# CPSW0_NUSS_CONTROL register map
Vendor: Texas Instruments
Peripheral module from a debugger description file (folder J7VCL).
Registers are 32-bit, read-write, reset 0x0 unless marked. A register's access mark holds for its fields unless they carry their own. Offsets are as the file gives them; lines under a group give offsets from that group; [hi:lo] are bit positions; {n}, {i} and the like mark numbered series; 'fields as' and 'values as' point back to an identical list; <NAME> marks a mode.

## CPSW0_NUSS_CONTROL
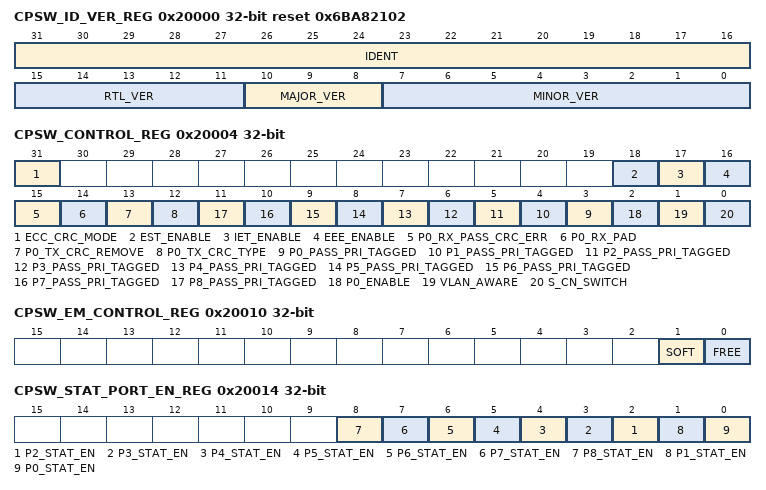
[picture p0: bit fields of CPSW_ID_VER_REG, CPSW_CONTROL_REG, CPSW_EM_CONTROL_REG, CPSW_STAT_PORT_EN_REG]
0x20000 CPSW_ID_VER_REG ro reset 0x6BA82102 — CPSW ID Version Register.
  [31:16] IDENT — Identification Value
  [15:11] RTL_VER — RTL Version Value
  [10:8] MAJOR_VER — Major Version Value
  [7:0] MINOR_VER — Minor Version Value
0x20004 CPSW_CONTROL_REG — CPSW Switch Control
  [31] ECC_CRC_MODE
  [18] EST_ENABLE — Enhanced Scheduled Traffic enable (EST)
  [17] IET_ENABLE — Intersperced Express Traffic enable (IET)
  [16] EEE_ENABLE — Energy Efficient Ethernet enable
  [15] P0_RX_PASS_CRC_ERR — Port 0 Pass Received CRC errors
  [14] P0_RX_PAD — Port 0 Receive Short Packet Pad
  [13] P0_TX_CRC_REMOVE — Port 0 Transmit CRC remove.
  [12] P0_TX_CRC_TYPE
  [n+3] P{n}_PASS_PRI_TAGGED (n=0..8) — Port {n} Pass Priority Tagged
  [2] P0_ENABLE — Port 0 Enable
  [1] VLAN_AWARE — VLAN Aware Mode:
  [0] S_CN_SWITCH — Service or Customer VLAN switch.
0x20010 CPSW_EM_CONTROL_REG — CPSW Emulation Control Register.
  [1] SOFT — Emulation Soft Bit
  [0] FREE — Emulation Free Bit
0x20014 CPSW_STAT_PORT_EN_REG — CPSW Statistics Port Enable Register.
  [n] P{n}_STAT_EN (n=2..8) — Port {n} Statistics Enable (if N &gt; {n})
  [1] P1_STAT_EN — Port 1 Statistics Enable
  [0] P0_STAT_EN — Port 0 Statistics Enable
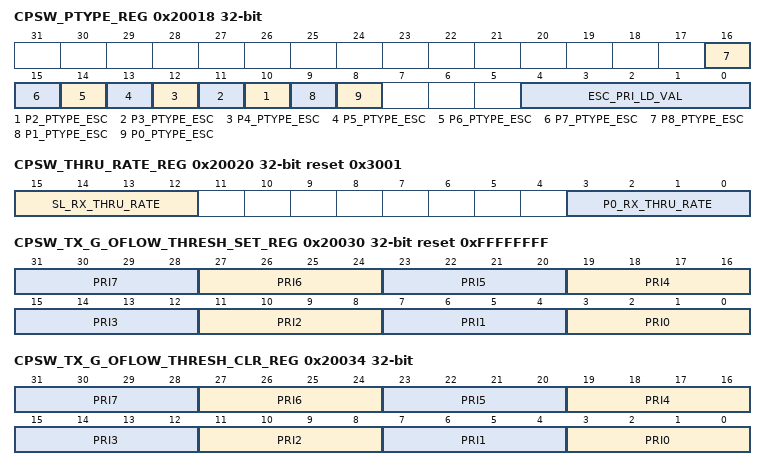
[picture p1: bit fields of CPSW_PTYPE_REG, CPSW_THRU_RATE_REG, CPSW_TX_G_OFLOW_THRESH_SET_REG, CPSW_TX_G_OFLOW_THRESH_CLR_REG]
0x20018 CPSW_PTYPE_REG — CPSW Transmit Priority Type.
  [n+8] P{n}_PTYPE_ESC (n=2..8) — Port {n} Priority Type Escalate (if N &gt; {n})
  [9] P1_PTYPE_ESC — Port 1 Priority Type Escalate
  [8] P0_PTYPE_ESC — Port 0 Priority Type Escalate
  [4:0] ESC_PRI_LD_VAL — Escalate Priority Load Value
0x2001C CPSW_SOFT_IDLE_REG — CPSW Software Idle Register.
  [0] SOFT_IDLE — Software Idle.
0x20020 CPSW_THRU_RATE_REG reset 0x3001 — CPSW Thru Rate Register.
  [15:12] SL_RX_THRU_RATE — Ethernet Port Switch FIFO receive through rate.
  [3:0] P0_RX_THRU_RATE — CPPI FIFO (port 0) receive through rate.
0x20024 CPSW_GAP_THRESH_REG reset 0xB — CPSW Transmit FIFO Short Gap Threshold Register.
  [4:0] GAP_THRESH — Ethernet Port Short Gap Threshold.
0x20028 CPSW_TX_START_WDS_REG reset 0x8 — CPSW Transmit FIFO Start Words Register
  [10:0] TX_START_WDS — FIFO Packet Transmit (egress) Start Words.
0x2002C CPSW_EEE_PRESCALE_REG — CPSW Energy Efficient Ethernet Prescale Value Register.
  [11:0] EEE_PRESCALE — Energy Efficient Ethernet Pre-scale count load value
0x20030 CPSW_TX_G_OFLOW_THRESH_SET_REG reset 0xFFFFFFFF — CPSW PFC Tx Global Out Flow Threshold Set
  [4n+3:4n] PRI{n} (n=0..7) — Priority Based Flow Control Global Outflow Usage Threshold for Pri {n}
0x20034 CPSW_TX_G_OFLOW_THRESH_CLR_REG — CPSW PFC Tx Global Out Flow Threshold Clear Register.
  fields as CPSW_TX_G_OFLOW_THRESH_SET_REG
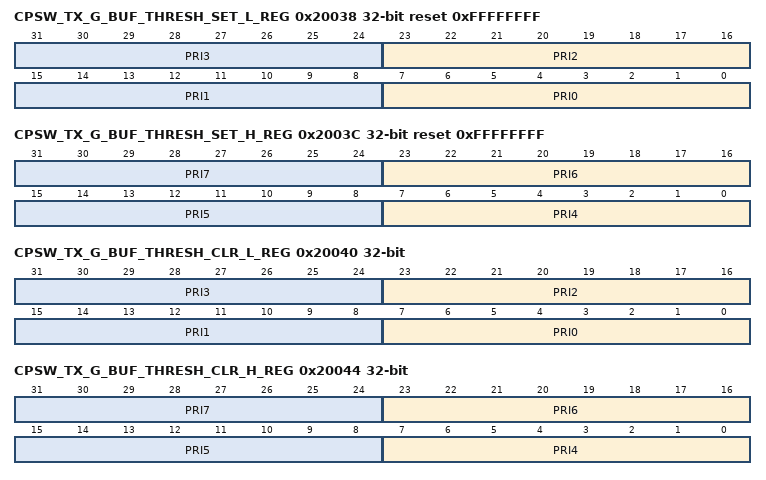
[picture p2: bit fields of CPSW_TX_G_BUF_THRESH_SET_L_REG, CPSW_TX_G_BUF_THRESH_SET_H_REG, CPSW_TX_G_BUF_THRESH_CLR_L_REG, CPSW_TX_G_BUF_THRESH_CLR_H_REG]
0x20038 CPSW_TX_G_BUF_THRESH_SET_L_REG reset 0xFFFFFFFF — CPSW PFC Global Tx Buffer Threshold Set Low Register.
  [8n+7:8n] PRI{n} (n=0..3) — Priority Based Flow Control Global Buffer Usage Threshold for Priority {n}
0x2003C CPSW_TX_G_BUF_THRESH_SET_H_REG reset 0xFFFFFFFF — CPSW PFC Global Tx Buffer Threshold Set High Register.
  [8n-25:8n-32] PRI{n} (n=4..7) — Priority Based Flow Control Global Buffer Usage Threshold for Priority {n}
0x20040 CPSW_TX_G_BUF_THRESH_CLR_L_REG — CPSW PFC Global Tx Buffer Threshold Clear Low Register.
  fields as CPSW_TX_G_BUF_THRESH_SET_L_REG
0x20044 CPSW_TX_G_BUF_THRESH_CLR_H_REG — CPSW PFC Global Tx Buffer Threshold Clear High Register.
  fields as CPSW_TX_G_BUF_THRESH_SET_H_REG
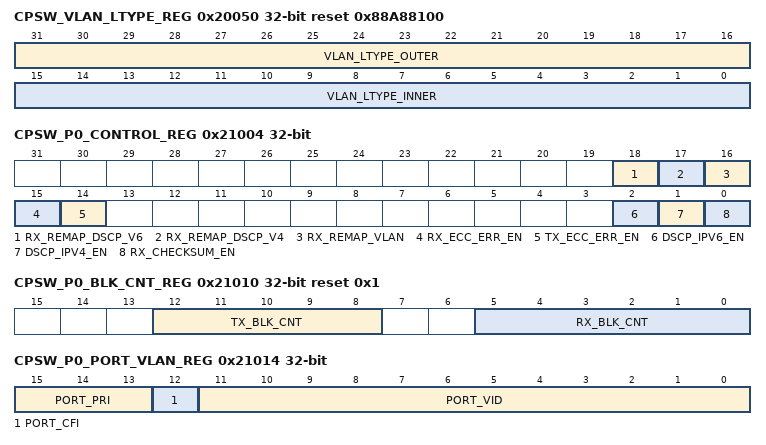
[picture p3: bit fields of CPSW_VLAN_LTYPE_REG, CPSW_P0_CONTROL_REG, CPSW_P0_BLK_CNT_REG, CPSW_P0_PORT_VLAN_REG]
0x20050 CPSW_VLAN_LTYPE_REG reset 0x88A88100 — VLAN LTYPE Outer and Inner Register.
  [31:16] VLAN_LTYPE_OUTER — Outer VLAN LType
  [15:0] VLAN_LTYPE_INNER — Inner VLAN LType
0x20054 CPSW_EST_TS_DOMAIN_REG — Enhanced Scheduled Traffic Host Event Domain Register.
  [7:0] EST_TS_DOMAIN — Enhanced Scheduled Traffic Host Event Domain.
{0x20100+4i} CPSW_TX_PRI{i}_MAXLEN_REG reset 0x7E8 (i=0..6) — Priority {i} Maximum Transmit Packet Length Register.
  [13:0] TX_PRI{i}_MAXLEN — Transmit Priority {i} Maximum Packet Length
0x2011C CPSW_TX_PRI7_MAXLEN_REG reset 0x7E8 — Priority 7 Maximum Transmit Packet Length Register.
  [13:0] TX_PRI7_MAXLEN — Transmit Priority 7 Maximum Packet Length.
0x21004 CPSW_P0_CONTROL_REG — CPPI Port 0 Control Register.
  [18] RX_REMAP_DSCP_V6 — Port 0 receive remap thread to DSCP IPV6 priority.
  [17] RX_REMAP_DSCP_V4 — Port 0 receive remap thread to DSCP IPV6 priority.
  [16] RX_REMAP_VLAN — Port 0 receive remap thread to VLAN.
  [15] RX_ECC_ERR_EN — Port 0 receive ECC Error Enable
  [14] TX_ECC_ERR_EN — Port 0 transmit ECC Error Enable
  [2] DSCP_IPV6_EN — Port 0 IPv6 DSCP enable
  [1] DSCP_IPV4_EN — Port 0 IPV4 DSCP enable
  [0] RX_CHECKSUM_EN — Port 0 Receive (port 0 ingress) Checksum Enable
0x21008 CPSW_P0_FLOW_ID_OFFSET_REG — CPPI Port 0 Flow ID Offset Register.
  [13:0] VALUE — This value is added to the thread/Flow_ID in CPPI transmit PSI Info Word 0
0x21010 CPSW_P0_BLK_CNT_REG ro reset 0x1 — CPPI Port 0 FIFO Block Usage Count Register.
  [12:8] TX_BLK_CNT — Port 0 Transmit Block Count Usage.
  [5:0] RX_BLK_CNT — Port 0 Receive Block Count Usage.
0x21014 CPSW_P0_PORT_VLAN_REG — CPPI Port 0 VLAN
  [15:13] PORT_PRI — Port VLAN Priority
  [12] PORT_CFI — Port CFI bit
  [11:0] PORT_VID — Port VLAN ID
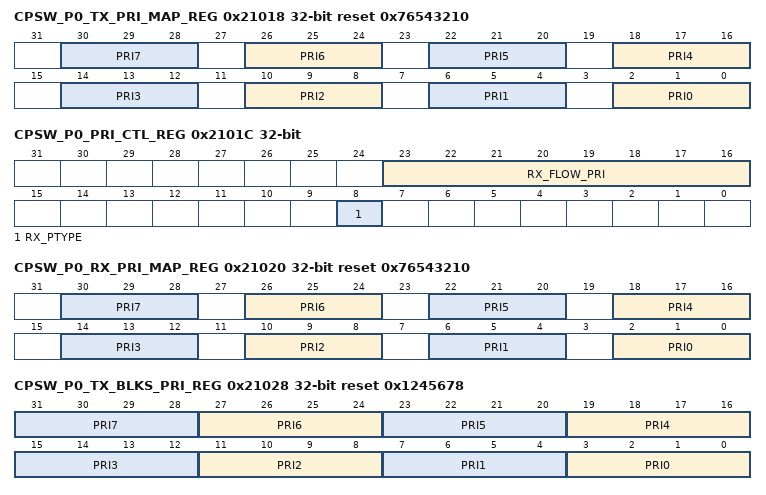
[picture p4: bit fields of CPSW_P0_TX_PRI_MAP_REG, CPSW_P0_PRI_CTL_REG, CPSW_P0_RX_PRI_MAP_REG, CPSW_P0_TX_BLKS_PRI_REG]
0x21018 CPSW_P0_TX_PRI_MAP_REG reset 0x76543210 — CPPI Port 0 Tx Header Pri to Switch Pri Mapping.
  [4n+2:4n] PRI{n} (n=0..7) — Priority {n}.
0x2101C CPSW_P0_PRI_CTL_REG — CPPI Port 0 Priority Control.
  [23:16] RX_FLOW_PRI — Receive Priority Based Flow Control Enable (per priority).
  [8] RX_PTYPE — Receive Priority Type
0x21020 CPSW_P0_RX_PRI_MAP_REG reset 0x76543210 — CPPI Port 0 RX Pkt Pri to Header Pri Map
  [4n+2:4n] PRI{n} (n=0..7) — Priority {n}.
0x21024 CPSW_P0_RX_MAXLEN_REG reset 0x5EE — CPPI Port 0 Receive Frame Max Length.
  [13:0] RX_MAXLEN — RX Maximum Frame Length.
0x21028 CPSW_P0_TX_BLKS_PRI_REG reset 0x1245678 — CPPI Port 0 Transmit Block Sub Per Priority Register.
  [4n+3:4n] PRI{n} (n=0..7) — Priority {n} Port Transmit Blocks
0x21030 CPSW_P0_IDLE2LPI_REG — Port 0 EEE LPI to wake counter load value.
  [23:0] COUNT — Port 0 EEE Idle to LPI counter load value
0x21034 CPSW_P0_LPI2WAKE_REG — Port 0 EEE LPI to wake counter
  [23:0] COUNT — Port 0 EEE LPI to wake counter load value
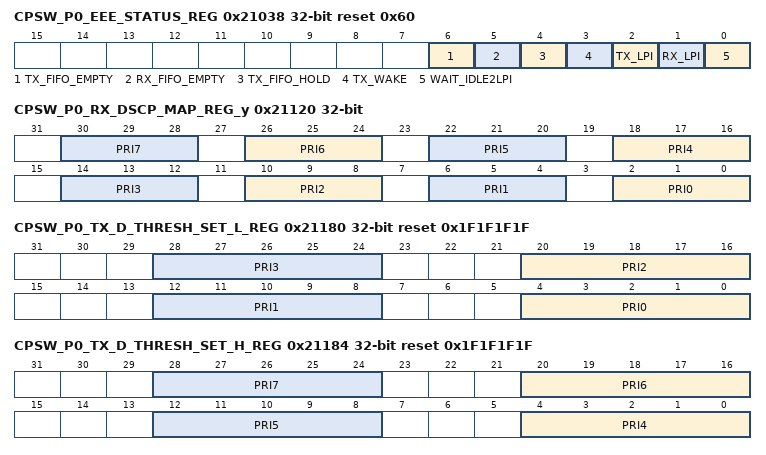
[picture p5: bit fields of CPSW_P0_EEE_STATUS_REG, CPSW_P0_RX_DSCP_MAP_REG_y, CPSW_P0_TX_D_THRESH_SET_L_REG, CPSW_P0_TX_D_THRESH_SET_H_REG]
0x21038 CPSW_P0_EEE_STATUS_REG ro reset 0x60 — Port 0 EEE status.
  [6] TX_FIFO_EMPTY — CPPI (Port 0) Transmit FIFO packet count zero.
  [5] RX_FIFO_EMPTY — CPPI (Port 0) Receive FIFO packet count zero.
  [4] TX_FIFO_HOLD — CPPI (Port 0) Transmit FIFO hold.
  [3] TX_WAKE — CPPI (Port 0) Receive Wake Time.
  [2] TX_LPI — CPPI (Port 0) transmit LPI state.
  [1] RX_LPI — CPPI (Port 0) receive LPI state.
  [0] WAIT_IDLE2LPI — CPPI (Port 0) Transmit Wait Idle to LPI.
0x21050 CPSW_P0_FIFO_STATUS_REG ro — Port 0 FIFO Status
  [7:0] TX_PRI_ACTIVE — Port 0 Transmit FIFO Priority Active.
0x21120 CPSW_P0_RX_DSCP_MAP_REG_y — CPPI Port 0 Receive IPV4/IPV6 DSCP Map 0 to Map 7 Registers. Offset = 00021120h + (y * 4h); where y = 0h to 7h
  [4n+2:4n] PRI{n} (n=0..7) — A DSCP IPV4/V6 packet TOS of N*8+{n} is mapped to this received priority
0x21140 CPSW_P0_PRI_CIR_REG_y — CPPI Port 0 Rx Priority 0 to Priority 7 Committed Information Rate Registers. Offset = 00021140h + (y * 4h); where y = 0h to 7h
  [27:0] PRI_CIR — Priority 'y' Committed Information Rate Count Value
0x21160 CPSW_P0_PRI_EIR_REG_y — CPPI Port 0 Rx Priority 0 to Priority 7 Excess Information Rate. Offset = 00021160h + (y * 4h); where y = 0h to 7h
  [27:0] PRI_EIR — Priority N EIR
0x21180 CPSW_P0_TX_D_THRESH_SET_L_REG reset 0x1F1F1F1F — CPPI Port 0 Tx PFC Destination Threshold Set Low
  [8n+4:8n] PRI{n} (n=0..3) — Port Priority Based Flow Control Threshold Set Value for Priority {n}
0x21184 CPSW_P0_TX_D_THRESH_SET_H_REG reset 0x1F1F1F1F — CPPI Port 0 Tx PFC Destination Threshold Set High
  [8n-28:8n-32] PRI{n} (n=4..7) — Port Priority Based Flow Control Threshold Set Value for Priority {n}
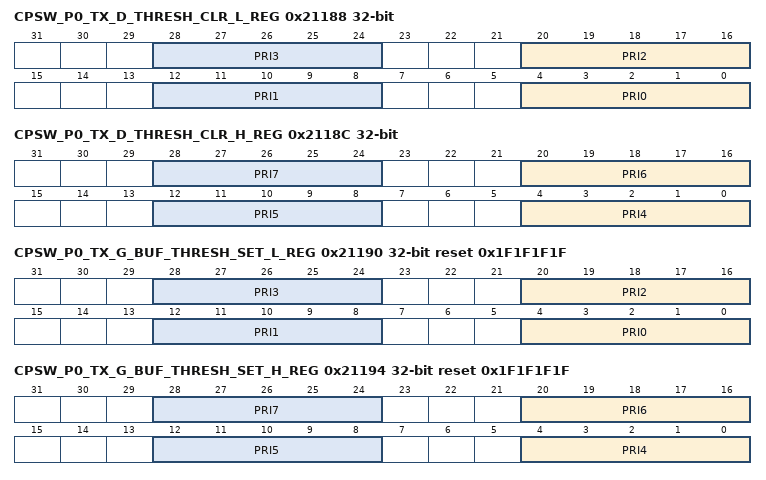
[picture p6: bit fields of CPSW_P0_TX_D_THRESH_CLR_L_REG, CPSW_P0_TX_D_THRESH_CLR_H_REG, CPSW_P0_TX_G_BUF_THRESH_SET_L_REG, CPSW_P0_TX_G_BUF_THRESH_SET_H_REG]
0x21188 CPSW_P0_TX_D_THRESH_CLR_L_REG — CPPI Port 0 Tx PFC Destination Threshold Clr Low
  [8n+4:8n] PRI{n} (n=0..3) — Port Priority Based Flow Control Threshold Clear Value for Priority {n}
0x2118C CPSW_P0_TX_D_THRESH_CLR_H_REG — CPPI Port 0 Tx PFC Destination Threshold Clr High
  [8n-28:8n-32] PRI{n} (n=4..7) — Port Priority Based Flow Control Threshold Clear Value for Priority {n}
0x21190 CPSW_P0_TX_G_BUF_THRESH_SET_L_REG reset 0x1F1F1F1F — CPPI Port 0 Tx PFC Global Buffer Threshold Set Low
  fields as CPSW_P0_TX_D_THRESH_SET_L_REG
0x21194 CPSW_P0_TX_G_BUF_THRESH_SET_H_REG reset 0x1F1F1F1F — CPPI Port 0 Tx PFC Global Buffer Threshold Set High
  fields as CPSW_P0_TX_D_THRESH_SET_H_REG
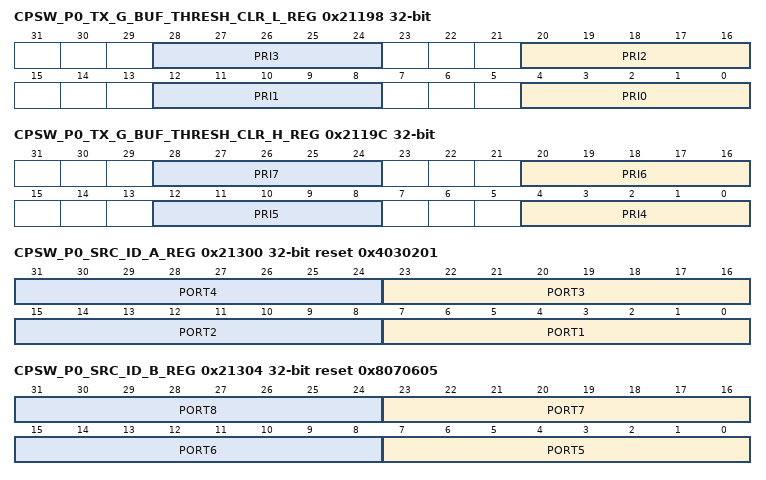
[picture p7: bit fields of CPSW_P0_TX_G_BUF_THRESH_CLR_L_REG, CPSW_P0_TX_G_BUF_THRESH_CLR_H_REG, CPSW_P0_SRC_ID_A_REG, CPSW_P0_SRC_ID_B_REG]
0x21198 CPSW_P0_TX_G_BUF_THRESH_CLR_L_REG — CPPI Port 0 Tx PFC Global Buffer Threshold Clr Low
  fields as CPSW_P0_TX_D_THRESH_CLR_L_REG
0x2119C CPSW_P0_TX_G_BUF_THRESH_CLR_H_REG — CPPI Port 0 Tx PFC Global Buffer Threshold Clr High
  fields as CPSW_P0_TX_D_THRESH_CLR_H_REG
0x21300 CPSW_P0_SRC_ID_A_REG reset 0x4030201 — CPPI Port 0 CPPI Source ID A.
  [8n-1:8n-8] PORT{n} (n=1..4) — Port {n} CPPI Info Word0 Source ID Value.
0x21304 CPSW_P0_SRC_ID_B_REG reset 0x8070605 — CPPI Port 0 CPPI Source ID B.
  [8n-33:8n-40] PORT{n} (n=5..8) — Port {n} CPPI Info Word0 Source ID Value.
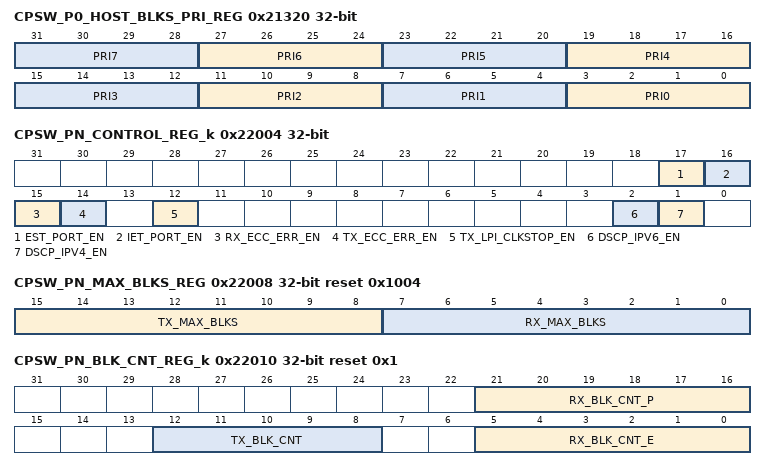
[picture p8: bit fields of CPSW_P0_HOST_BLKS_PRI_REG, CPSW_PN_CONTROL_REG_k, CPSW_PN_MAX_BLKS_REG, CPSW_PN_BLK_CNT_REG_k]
0x21320 CPSW_P0_HOST_BLKS_PRI_REG — CPPI Port 0 Host Blocks Priority
  [4n+3:4n] PRI{n} (n=0..7) — Priority {n} Host Blocks
0x22000 CPSW_PN_RESERVED_REG_k ro — Reserved.
0x22004 CPSW_PN_CONTROL_REG_k — Enet Port N Control. Offset = 00022004h + (k * 1000h); where k = 0h to 3h
  [17] EST_PORT_EN — EST Port Enable.
  [16] IET_PORT_EN — Intersperced Express Traffic (IET) Port Enable.
  [15] RX_ECC_ERR_EN — Port N receive ECC Error Enable
  [14] TX_ECC_ERR_EN — Port N transmit ECC Error Enable
  [12] TX_LPI_CLKSTOP_EN — Transmit LPI Clock Stop Enable.
  [2] DSCP_IPV6_EN — IPV6 DSCP enable
  [1] DSCP_IPV4_EN — IPV4 DSCP enable
0x22008 CPSW_PN_MAX_BLKS_REG reset 0x1004 — Enet Port N FIFO Max Blocks.
  [15:8] TX_MAX_BLKS — Transmit Max Blocks.
  [7:0] RX_MAX_BLKS — Receive Max Blocks.
0x22010 CPSW_PN_BLK_CNT_REG_k ro reset 0x1 — Enet Port N FIFO Block Usage Count Offset = 00022010h + (N * 1000h); where k = 0h to 3h
  [21:16] RX_BLK_CNT_P — Receive Express Block Count Usage.
  [12:8] TX_BLK_CNT — Transmit Block Count Usage.
  [5:0] RX_BLK_CNT_E — Receive Express Block Count Usage.
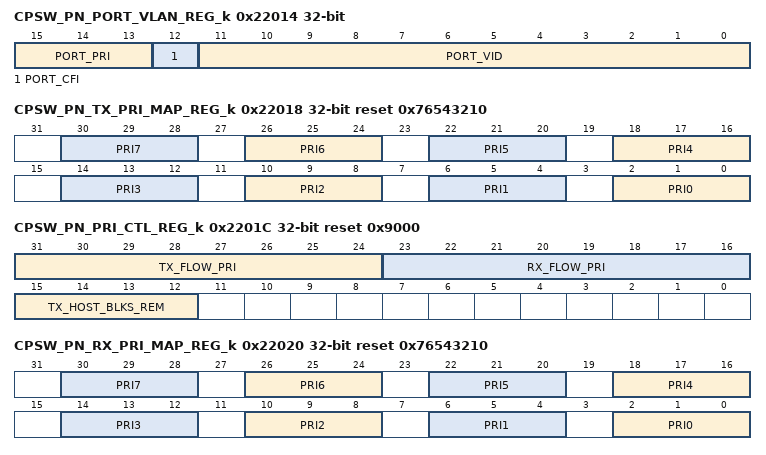
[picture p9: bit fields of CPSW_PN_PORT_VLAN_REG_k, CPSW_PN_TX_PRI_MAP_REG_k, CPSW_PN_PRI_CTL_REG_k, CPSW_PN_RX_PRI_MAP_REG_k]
0x22014 CPSW_PN_PORT_VLAN_REG_k — Enet Port N VLAN Offset = 00022014h + (k * 1000h); where k = 0h to 3h
  fields as CPSW_P0_PORT_VLAN_REG
0x22018 CPSW_PN_TX_PRI_MAP_REG_k reset 0x76543210 — Enet Port N Tx Header Pri to Switch Pri Mapping Offset = 00022018h + (k * 1000h); where k = 0h to 3h
  [4n+2:4n] PRI{n} (n=0..7) — Priority {n}. A packet header priority of {n}h is given this switch queue pri.
0x2201C CPSW_PN_PRI_CTL_REG_k reset 0x9000 — Enet Port N Priority Control Offset = 0002201Ch + (k * 1000h); where k = 0h to 3h
  [31:24] TX_FLOW_PRI — Transmit Priority Based Flow Control Enable (per priority)
  [23:16] RX_FLOW_PRI — Receive Priority Based Flow Control Enable (per priority)
  [15:12] TX_HOST_BLKS_REM — Transmit FIFO Blocks that must be free before a non rate-limited CPPI Port 0 receive thread can begin sending a packet
0x22020 CPSW_PN_RX_PRI_MAP_REG_k reset 0x76543210 — Enet Port N RX Pkt Pri to Header Pri Map Offset = 00022020h + (k * 1000h); where k = 0h to 3h
  [4n+2:4n] PRI{n} (n=0..7) — Priority {n}.
0x22024 CPSW_PN_RX_MAXLEN_REG_k reset 0x5EE — Enet Port N Receive Frame Max Length. Offset = 00022024h + (k * 1000h); where k = 0h to 3h
  [13:0] RX_MAXLEN — RX Maximum Frame Length.
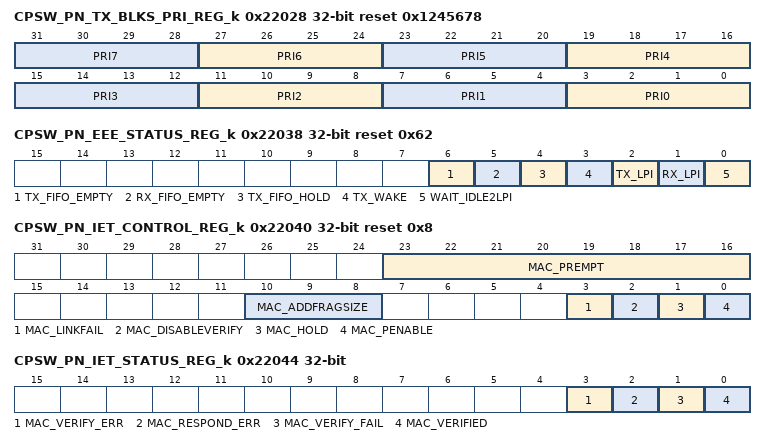
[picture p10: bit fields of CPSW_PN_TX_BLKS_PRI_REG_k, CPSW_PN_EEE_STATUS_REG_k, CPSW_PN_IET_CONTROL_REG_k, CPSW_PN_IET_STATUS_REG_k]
0x22028 CPSW_PN_TX_BLKS_PRI_REG_k reset 0x1245678 — Enet Port N Transmit Block Sub Per Priority Offset = 00022028h + (k * 1000h); where k = 0h to 3h
  [4n+3:4n] PRI{n} (n=0..7) — Priority {n} Port Transmit Blocks
0x22030 CPSW_PN_IDLE2LPI_REG_k — Enet Port N EEE Idle to LPI counter Offset = 00022030h + (k * 1000h); where k = 0h to 3h
  [23:0] COUNT — EEE Idle to LPI counter load value
0x22034 CPSW_PN_LPI2WAKE_REG_k — Enet Port N EEE LPI to wake counter Offset = 00022034h + (k * 1000h); where k = 0h to 3h
  [23:0] COUNT — EEE LPI to wake counter load value
0x22038 CPSW_PN_EEE_STATUS_REG_k ro reset 0x62 — Enet Port N EEE status Offset = 00022038h + (k * 1000h); where k = 0h to 3h
  [6] TX_FIFO_EMPTY — Port N Transmit FIFO packet count zero.
  [5] RX_FIFO_EMPTY — Port N Receive FIFO packet count zero.
  [4] TX_FIFO_HOLD — Port N Transmit FIFO hold.
  [3] TX_WAKE — Port N Receive Wake Time.
  [2] TX_LPI — Port N Transmit LPI.
  [1] RX_LPI — Port N Receive LPI.
  [0] WAIT_IDLE2LPI — Transmit Wait Idle to LPI.
0x22040 CPSW_PN_IET_CONTROL_REG_k reset 0x8 — Enet Port N IET Control Offset = 00022040h + (k * 1000h); where k = 0h to 3h
  [23:16] MAC_PREMPT — Mac Preempt Queue – Indicates which transmit FIFO queues are sent to the preempt MAC. Bit 0 indicates queue zero, bit 1 queue 1 and so on. Packets will be sent to the preempt MAC only when MAC_PENABLE is set, and when MAC_VERIFIED (fromCPSW_PN_IET_STATUS_REG_k) or MAC_DISABLEVERIFY is set, and when IET_PORT_EN is set.
  [10:8] MAC_ADDFRAGSIZE — Mac Fragment Size – An integer in the range 0:7 indicating, as a multiple of 64, the minimum additional length for nonfinal mPackets. 0 = 64 1 = 128 2 = 192 3 = 256 4 = 320 5 = 384 6 = 448 7 = 512
  [3] MAC_LINKFAIL — Mac Link Fail – Link Fail Indicator to reset the verify state machine. This bit is reset high. Verify and response frames will be sent/allowed when this bit is cleared.
  [2] MAC_DISABLEVERIFY — Mac Disable Verify – Disables verification on the port when set. If this bit is set then packets will be sent to the preempt Mac when MAC_PENABLE is set (This is a forced mode with no IET verification).
  [1] MAC_HOLD — Mac Hold – Hold Preemption on the port.
  [0] MAC_PENABLE — Mac Preemption Enable – Port Preemption Enable. This takes effect only when IET_PORT_EN is set.
0x22044 CPSW_PN_IET_STATUS_REG_k ro — Enet Port N IET Status Offset = 00022044h + (k * 1000h); where k = 0h to 3h
  [3] MAC_VERIFY_ERR — Mac Received Verify Packet with Errors – Set when a verify packet with errors is received. Cleared when MAC_PENABLE is cleared to zero.
  [2] MAC_RESPOND_ERR — Mac Received Respond Packet with Errors – Set when a respond packet with errors is received. Cleared when MAC_PENABLE is cleared to zero.
  [1] MAC_VERIFY_FAIL — Mac Verification Failed – Indication that verification was unsuccessful.
  [0] MAC_VERIFIED — Mac Verified – Indication that verification was successful.
0x22048 CPSW_PN_IET_VERIFY_REG_k reset 0x1312D0 — Enet Port N IET VERIFY Offset = 00022048h + (k * 1000h); where k = 0h to 3h
  [23:0] MAC_VERIFY_CNT — Mac Verify Timeout Count – The number of wireside clocks contained in the verify timeout counter. The default is 0x1312D0 (10ms at 125MHz in gig mode).
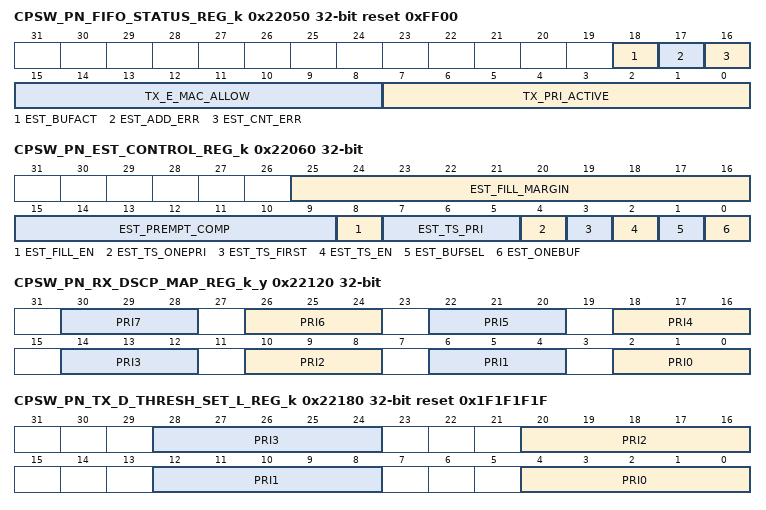
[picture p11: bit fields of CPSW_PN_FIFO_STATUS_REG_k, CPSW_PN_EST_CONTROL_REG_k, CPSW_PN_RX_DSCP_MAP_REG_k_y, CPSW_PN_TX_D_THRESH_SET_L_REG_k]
0x22050 CPSW_PN_FIFO_STATUS_REG_k ro reset 0xFF00 — Enet Port N FIFO STATUS Offset = 00022050h + (k * 1000h); where k = 0h to 3h
  [18] EST_BUFACT — EST RAM active buffer.
  [17] EST_ADD_ERR — EST Address Error.
  [16] EST_CNT_ERR — EST Fetch Count Error.
  [15:8] TX_E_MAC_ALLOW — EST transmit MAC allow.
  [7:0] TX_PRI_ACTIVE — EST Transmit Priority Active.
0x22060 CPSW_PN_EST_CONTROL_REG_k — Enet Port N EST CONTROL Offset = 00022060h + (k * 1000h); where k = 0h to 3h
  [25:16] EST_FILL_MARGIN
  [15:9] EST_PREMPT_COMP — EST Prempt Comparison Value.
  [8] EST_FILL_EN — EST Fill Enable.
  [7:5] EST_TS_PRI — EST Timestamp Express Priority.
  [4] EST_TS_ONEPRI — EST Timestamp One Express Priority.
  [3] EST_TS_FIRST — EST Timestamp First Express Packet only.
  [2] EST_TS_EN — EST Timestamp Enable.
  [1] EST_BUFSEL — EST Buffer Select.
  [0] EST_ONEBUF — EST One Fetch Buffer.
0x22120 CPSW_PN_RX_DSCP_MAP_REG_k_y — Enet Port N Receive IPV4/IPV6 DSCP Map M Offset = 00022120h + (k * 1000h) + (y * 4h); where k = 0h to 3h, y = 0h to 7h
  fields as CPSW_P0_RX_DSCP_MAP_REG_y
0x22140 CPSW_PN_PRI_CIR_REG_k_y — Enet Port N Rx Priority P Committed Information Rate Value Offset = 00022140h + (k * 1000h) + (y * 4h); where k = 0h to 3h, y = 0h to 7h
  [27:0] PRI_CIR — Priority N committed information rate
0x22160 CPSW_PN_PRI_EIR_REG_k_y — Enet Port N Rx Priority P Excess Informatoin Rate Value. Offset = 00022160h + (k * 1000h) + (y * 4h); where k = 0h to 3h, y = 0h to 7h
  [27:0] PRI_EIR — Priority N Excess Information Rate count
0x22180 CPSW_PN_TX_D_THRESH_SET_L_REG_k reset 0x1F1F1F1F — Enet Port N Tx PFC Destination Threshold Set Low. Offset = 00022180h + (k * 1000h); where k = 0h to 3h
  fields as CPSW_P0_TX_D_THRESH_SET_L_REG
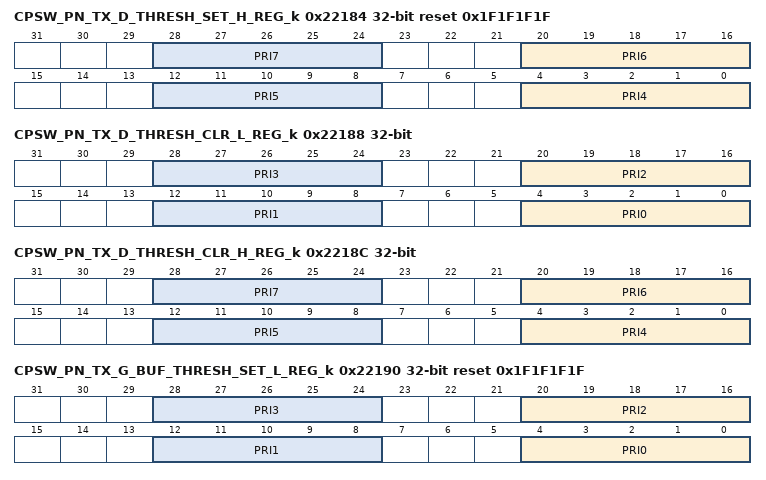
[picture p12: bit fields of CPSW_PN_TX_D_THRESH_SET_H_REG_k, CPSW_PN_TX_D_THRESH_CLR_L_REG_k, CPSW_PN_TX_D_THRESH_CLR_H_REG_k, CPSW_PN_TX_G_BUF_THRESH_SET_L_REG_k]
0x22184 CPSW_PN_TX_D_THRESH_SET_H_REG_k reset 0x1F1F1F1F — Enet Port N Tx PFC Destination Threshold Set High. Offset = 00022184h + (k * 1000h); where k = 0h to 3h
  fields as CPSW_P0_TX_D_THRESH_SET_H_REG
0x22188 CPSW_PN_TX_D_THRESH_CLR_L_REG_k — Enet Port N Tx PFC Destination Threshold Clr Low. Offset = 00022188h + (k * 1000h); where k = 0h to 3h
  fields as CPSW_P0_TX_D_THRESH_CLR_L_REG
0x2218C CPSW_PN_TX_D_THRESH_CLR_H_REG_k — Enet Port N Tx PFC Destination Threshold Clr High. Offset = 0002218Ch + (k * 1000h); where k = 0h to 3h
  fields as CPSW_P0_TX_D_THRESH_CLR_H_REG
0x22190 CPSW_PN_TX_G_BUF_THRESH_SET_L_REG_k reset 0x1F1F1F1F — Enet Port N Tx PFC Global Buffer Threshold Set Low. Offset = 00022190h + (k * 1000h); where k = 0h to 3h
  fields as CPSW_P0_TX_D_THRESH_SET_L_REG
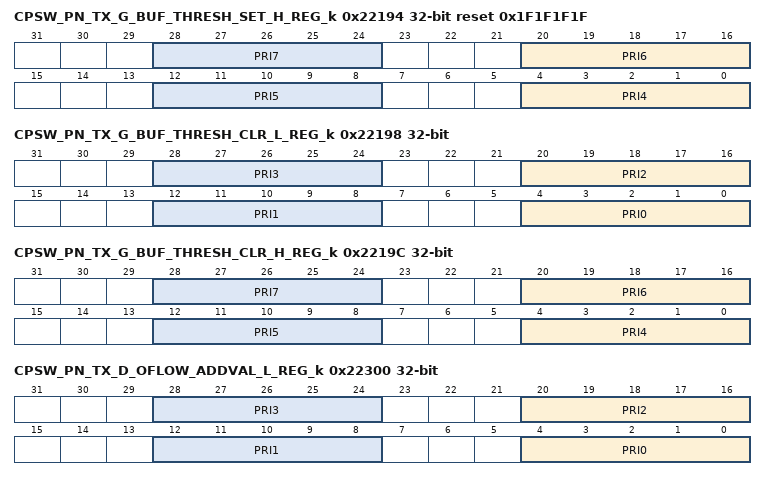
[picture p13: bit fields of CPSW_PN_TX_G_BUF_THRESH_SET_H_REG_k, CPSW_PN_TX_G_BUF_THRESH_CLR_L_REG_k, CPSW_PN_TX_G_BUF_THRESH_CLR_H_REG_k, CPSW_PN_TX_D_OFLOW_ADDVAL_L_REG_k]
0x22194 CPSW_PN_TX_G_BUF_THRESH_SET_H_REG_k reset 0x1F1F1F1F — Enet Port N Tx PFC Global Buffer Threshold Set High. Offset = 00022194h + (k * 1000h); where k = 0h to 3h
  fields as CPSW_P0_TX_D_THRESH_SET_H_REG
0x22198 CPSW_PN_TX_G_BUF_THRESH_CLR_L_REG_k — Enet Port N Tx PFC Global Buffer Threshold Clr Low Offset = 00022198h + (k * 1000h); where k = 0h to 3h
  fields as CPSW_P0_TX_D_THRESH_CLR_L_REG
0x2219C CPSW_PN_TX_G_BUF_THRESH_CLR_H_REG_k — Enet Port N Tx PFC Global Buffer Threshold Clr High Offset = 0002219Ch + (k * 1000h); where k = 0h to 3h
  fields as CPSW_P0_TX_D_THRESH_CLR_H_REG
0x22300 CPSW_PN_TX_D_OFLOW_ADDVAL_L_REG_k — Enet Port N Tx Destination Out Flow Add Values Low. Offset = 00022300h + (k * 1000h); where k = 0h to 3h
  [8n+4:8n] PRI{n} (n=0..3) — Port PFC Destination Based Out Flow Add Value for Priority {n}
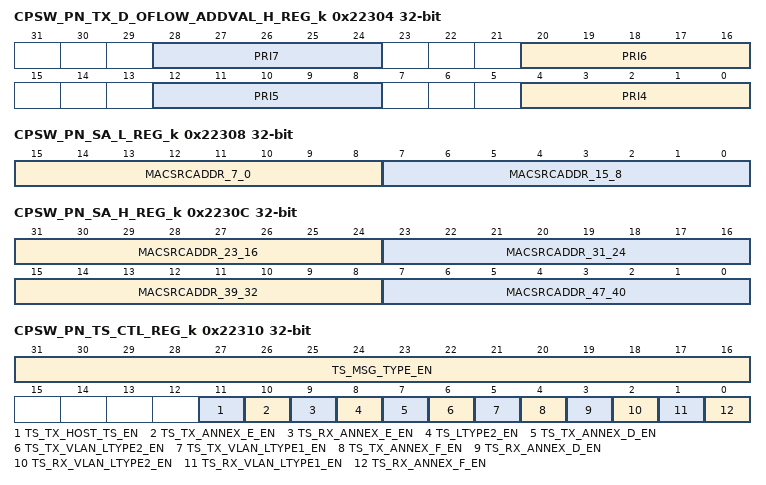
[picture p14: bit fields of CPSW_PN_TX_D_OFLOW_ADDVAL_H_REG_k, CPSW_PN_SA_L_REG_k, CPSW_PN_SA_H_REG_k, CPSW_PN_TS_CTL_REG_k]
0x22304 CPSW_PN_TX_D_OFLOW_ADDVAL_H_REG_k — Enet Port N Tx Destination Out Flow Add Values High. Offset = 00022304h + (k * 1000h); where k = 0h to 3h
  [8n-28:8n-32] PRI{n} (n=4..7) — Port PFC Destination Based Out Flow Add Value for Priority {n}
0x22308 CPSW_PN_SA_L_REG_k — Enet Port N Tx Pause Frame Source Address Low Offset = 00022308h + (k * 1000h); where k = 0h to 3h
  [15:8] MACSRCADDR_7_0 — Source Address Lower 8 bits (byte 0)
  [7:0] MACSRCADDR_15_8 — Source Address bits 15-8 (byte 1)
0x2230C CPSW_PN_SA_H_REG_k — Enet Port N Tx Pause Frame Source Address High. Offset = 0002230Ch + (k * 1000h); where k = 0h to 3h
  [31:24] MACSRCADDR_23_16 — Source Address bits 23-16 (byte 2)
  [23:16] MACSRCADDR_31_24 — Source Address bits 31-24 (byte 3)
  [15:8] MACSRCADDR_39_32 — Source Address bits 39-32 (byte 4)
  [7:0] MACSRCADDR_47_40 — Source Address bits 47-40 (byte 5)
0x22310 CPSW_PN_TS_CTL_REG_k — Enet Port N Time Sync Control Offset = 00022310h + (k * 1000h); where k = 0h to 3h
  [31:16] TS_MSG_TYPE_EN — Time Sync Message Type Enable.
  [11] TS_TX_HOST_TS_EN — Time Sync Transmit Host Time Stamp Enable.
  [10] TS_TX_ANNEX_E_EN — Time Sync Transmit Annex E enable.
  [9] TS_RX_ANNEX_E_EN — Time Sync Receive Annex E enable.
  [8] TS_LTYPE2_EN — Time Sync LTYPE 2 enable (transmit and receive).
  [7] TS_TX_ANNEX_D_EN — Time Sync Transmit Annex D enable.
  [6] TS_TX_VLAN_LTYPE2_EN — Time Sync Transmit VLAN LTYPE 2 enable.
  [5] TS_TX_VLAN_LTYPE1_EN — Time Sync Transmit VLAN LTYPE 1 enable.
  [4] TS_TX_ANNEX_F_EN — Time Sync Transmit Annex F enable.
  [3] TS_RX_ANNEX_D_EN — Time Sync Receive Annex D enable.
  [2] TS_RX_VLAN_LTYPE2_EN — Time Sync Receive VLAN LTYPE 2 enable.
  [1] TS_RX_VLAN_LTYPE1_EN — Time Sync Receive VLAN LTYPE 1 enable.
  [0] TS_RX_ANNEX_F_EN — Time Sync Receive Annex F Enable.
0x22314 CPSW_PN_TS_SEQ_LTYPE_REG_k reset 0x1E0000 — Enet Port N Time Sync LTYPE (and SEQ_ID_OFFSET). Offset = 00022314h + (k * 1000h); where k = 0h to 3h
  [21:16] TS_SEQ_ID_OFFSET — Time Sync Sequence ID Offset
  [15:0] TS_LTYPE1 — Time Sync LTYPE1
0x22318 CPSW_PN_TS_VLAN_LTYPE_REG_k — Enet Port N Time Sync VLAN2 and VLAN2. Offset = 00022318h + (k * 1000h); where k = 0h to 3h
  [31:16] TS_VLAN_LTYPE2 — Time Sync VLAN LTYPE2
  [15:0] TS_VLAN_LTYPE1 — Time Sync VLAN LTYPE1
0x2231C CPSW_PN_TS_CTL_LTYPE2_REG_k — Enet Port N Time Sync Control and LTYPE 2. Offset = 0002231Ch + (k * 1000h); where k = 0h to 3h
  [24] TS_UNI_EN — Time Sync Unicast Enable
  [23] TS_TTL_NONZERO — Time Sync Time to Live Non-zero Enable
  [22] TS_320 — Time Sync Destination IP Address 320 Enable
  [21] TS_319 — Time Sync Destination IP Address 319 Enable
  [n-112] TS_{n} (n=129..132) — Time Sync Destination IP Address {n} Enable
  [16] TS_107 — Time Sync Destination IP Address 107 Enable
  [15:0] TS_LTYPE2 — Time Sync LTYPE2
0x22320 CPSW_PN_TS_CTL2_REG_k reset 0x40000 — Enet Port N Time Sync Control 2. Offset = 00022320h + (k * 1000h); where k = 0h to 3h
  [21:16] TS_DOMAIN_OFFSET — Time Sync Domain Offset
  [15:0] TS_MCAST_TYPE_EN — Time Sync Multicast Destination Address Type Enable
0x22330 CPSW_PN_MAC_CONTROL_REG_k — Enet Port N Mac Control. Offset = 00022330h + (k * 1000h); where k = 0h to 3h
  [25] EXT_EN_XGIG — 10G External Enable
  [24] RX_CMF_EN — RX Copy MAC Control Frames Enable.
  [23] RX_CSF_EN — RX Copy Short Frames Enable.
  [22] RX_CEF_EN — RX Copy Error Frames Enable.
  [21] TX_SHORT_GAP_LIM_EN — Transmit Short Gap Limit Enable
  [20] EXT_TX_FLOW_EN — External Transmit Flow Control Enable.
  [19] EXT_RX_FLOW_EN — External Receive Flow Control Enable.
  [18] EXT_EN — External Control Enable.
  [17] GIG_FORCE — Gigabit Mode Force.
  [16] IFCTL_B — Interface Control B.
  [15] IFCTL_A — Interface Control A.
  [13] XGMII_EN — XGMII Enable.
  [12] CRC_TYPE — Port CRC Type.
  [11] CMD_IDLE — Command Idle.
  [10] TX_SHORT_GAP_ENABLE — Transmit Short Gap Enable.
  [8] XGIG — 10 Gigabit Mode.Note: 10 Gigabit Mode is not supported on this device.
  [7] GIG — Gigabit Mode.
  [6] TX_PACE — Transmit Pacing Enable
  [5] GMII_EN — GMII Enable.
  [4] TX_FLOW_EN — Transmit Flow Control Enable.
  [3] RX_FLOW_EN — Receive Flow Control Enable.
  [2] MTEST — Manufacturing Test mode.
  [1] LOOPBACK — Loop Back Mode.
  [0] FULLDUPLEX — Full Duplex mode.
0x22334 CPSW_PN_MAC_STATUS_REG_k ro reset 0xF0000000 — Enet Port N Mac Status Offset = 00022334h + (k * 1000h); where k = 0h to 3h
  [31] IDLE — Enet IDLE.
  [30] E_IDLE — Express MAC is Idle.
  [29] P_IDLE — Prempt MAC is Idle.
  [28] MAC_TX_IDLE — Mac Transmit Idle.
  [27] TORF — Top of receive FIFO flow control trigger occurred.
  [26:24] TORF_PRI — The lowest priority that caused top of receive FIFO flow control trigger since the last write to clear.
  [23:16] TX_PFC_FLOW_ACT — Transmit Priority Based Flow Control Active (priority 7 down to 0)
  [15:8] RX_PFC_FLOW_ACT — Receive Priority Based Flow Control Active (priority 7 down to 0)
  [6] EXT_RX_FLOW_EN — External Receive Flow Control Enable.
  [5] EXT_TX_FLOW_EN — External Transmit Flow Control Enable.
  [4] EXT_GIG — External GIG.
  [3] EXT_FULLDUPLEX — External Fullduplex.
  [1] RX_FLOW_ACT — Receive Flow Control Active.
  [0] TX_FLOW_ACT — Transmit Flow Control Active.
0x22338 CPSW_PN_MAC_SOFT_RESET_REG_k — Enet Port N Mac Soft Reset. Offset = 00022338h + (k * 1000h); where k = 0h to 3h
  [0] SOFT_RESET — Software reset.
0x2233C CPSW_PN_MAC_BOFFTEST_REG_k access per field — Enet Port N Mac Backoff Test Offset = 0002233Ch + (k * 1000h); where k = 0h to 3h
  [30:26] PACEVAL rw — Pacing Current Value.
  [25:16] RNDNUM rw — Backoff Random Number Generator.
  [15:12] COLL_COUNT ro — Collision Count.
  [9:0] TX_BACKOFF ro — Backoff Count.
0x22340 CPSW_PN_MAC_RX_PAUSETIMER_REG_k — Enet Port N 802.3 Receive Pause Timer Offset = 00022340h + (k * 1000h); where k = 0h to 3h
  [15:0] RX_PAUSETIMER — RX Pause Timer Value.
0x22350 CPSW_PN_MAC_RXN_PAUSETIMER_REG_k_y — Ethernet Port N PFC Priority 0 to Priority 7 Rx Pause Timer Registers. Offset = 00022350h + (k * 1000h) + (y * 4h); where k = 0h to 3h, y = 0h to 7h
  [15:0] RX_PAUSETIMER — Rx “y” Pause Timer Value.
0x22370 CPSW_PN_MAC_TX_PAUSETIMER_REG_k — Enet Port N 802.3 Tx Pause Timer. Offset = 00022370h + (k * 1000h); where k = 0h to 3h
  [15:0] TX_PAUSETIMER — 802.3 Tx Pause Timer Value.
0x22380 CPSW_PN_MAC_TXN_PAUSETIMER_REG_k_y — Ethernet Port N PFC Priority 0 to Priority 7 Tx Pause Timer Registers. Offset = 00022380h + (k * 1000h) + (y * 4h); where k = 0h to 3h, y = 0h to 7h
  [15:0] TX_PAUSETIMER — PFC Tx ”y” Pause Timer Value.
0x223A0 CPSW_PN_MAC_EMCONTROL_REG_k — Enet Port N Emulation Control. Offset = 000223A0h + (k * 1000h); where k = 0h to 3h
  [1] SOFT — Emulation Soft Bit
  [0] FREE — Emulation Free Bit
0x223A4 CPSW_PN_MAC_TX_GAP_REG_k reset 0xC — Enet Port N Tx Inter Packet Gap. Offset = 000223A4h + (k * 1000h); where k = 0h to 3h
  [15:0] TX_GAP — Transmit Inter-Packet Gap
0x223A8 CPSW_PN_MAC_PORT_CONFIG_k ro reset 0x310 — Return to the . Enet Port N Port Configuration Offset = 000223A8h + (k * 1000h); where k = 0h to 3h
  [9] IET — Intersperced Express Traffic (IET) is supported on this port when read high.
  [8] XGMII — XGMII is supported on this port when set.
  [7:0] INTERVLAN_ROUTES — This is the number of InterVLAN routes supported on this port (egress).
0x223AC CPSW_PN_INTERVLAN_OPX_POINTER_REG_k — Enet Port N Tx Egress InterVLAN Operation Pointer Offset = 000223ACh + (k * 1000h); where k = 0h to 3h
  [4:0] POINTER — InterVLAN location pointer: This field points to the InterVLAN location that will be read/written by accesses to Enet_Pn_InterVLANx_A/B.
0x223B0 CPSW_PN_INTERVLAN_OPX_A_REG_k — Enet Port N Tx Egress InterVLAN A Offset = 000223B0h + (k * 1000h); where k = 0h to 3h
  [31:24] DA_23_16 — Destination Address bits 23:16 – DA byte 4 on wire
  [23:16] DA_31_24 — Destination Address bits 31:24 – DA byte 3 on wire
  [15:8] DA_39_32 — Destination Address bits 39:32 – DA byte 2 on wire
  [7:0] DA_47_40 — Destination Address bits 47:40 – DA byte 1 on wire
0x223B4 CPSW_PN_INTERVLAN_OPX_B_REG_k — Enet Port N Tx Egress InterVLAN B Offset = 000223B4h + (k * 1000h); where k = 0h to 3h
  [31:24] SA_39_32 — Source Address bits 39:32 – SA byte 2 on wire
  [23:16] SA_47_40 — Source Address bits 47:40 – SA byte 1 on wire
  [15:8] DA_7_0 — Destination Address bits 7:0 – DA byte 6 on wire
  [7:0] DA_15_8 — Destination Address bits 15:8 – DA byte 5 on wire
0x223B8 CPSW_PN_INTERVLAN_OPX_C_REG_k — Enet Port N Tx Egress InterVLAN C Offset = 000223B8h + (k * 1000h); where k = 0h to 3h
  [31:24] SA_7_0 — Source Address bits 7:0 – DA byte 6 on wire
  [23:16] SA_15_8 — Source Address bits 15:8 – DA byte 5 on wire
  [15:8] SA_23_16 — Source Address bits 23:16 – DA byte 4 on wire
  [7:0] SA_31_24 — Source Address bits 31:24 – DA byte 3 on wire
0x223BC CPSW_PN_INTERVLAN_OPX_D_REG_k — Enet Port N Tx Egress InterVLAN D. Offset = 000223BCh + (k * 1000h); where k = 0h to 3h
  [15] DECREMENT_TTL — Decrement Time To Live.IPV4 – Decrement the TTL byte and update the Header ChecksumIPV6 – Decrement the Hop Limit.Note: When this bit is set, the ALE should be configured to send any IPv4/6 packet with a zero or one TTL field to the host with the ALE egress operation ttl_check bit.When this bit is cleared the TTL/Hop Limit fields are not checked or modified.
  [14] DEST_FORCE_UNTAGGED_EGRESS — Destination VLAN Force Untagged Egress.
  [13] REPLACE_DA_SA — Replace Destination Address and Source Address.
  [12] REPLACE_VID — Replace VLAN ID.
  [11:0] VID — VLAN ID
